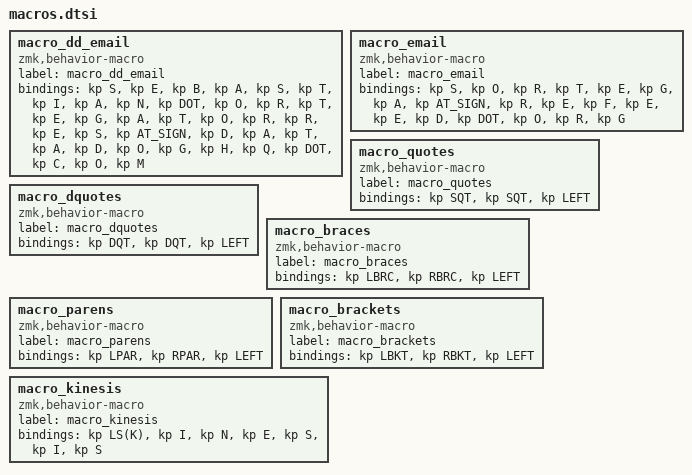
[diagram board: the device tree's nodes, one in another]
macro_dd_email: macro_dd_email{
compatible = "zmk,behavior-macro";
label = "macro_dd_email";
#binding-cells = <0>;
bindings = <&kp S>, <&kp E>, <&kp B>, <&kp A>, <&kp S>, <&kp T>, <&kp I>, <&kp A>, <&kp N>, <&kp DOT>, <&kp O>, <&kp R>, <&kp T>, <&kp E>, <&kp G>, <&kp A>, <&kp T>, <&kp O>, <&kp R>, <&kp R>, <&kp E>, <&kp S>, <&kp AT_SIGN>, <&kp D>, <&kp A>, <&kp T>, <&kp A>, <&kp D>, <&kp O>, <&kp G>, <&kp H>, <&kp Q>, <&kp DOT>, <&kp C>, <&kp O>, <&kp M>;
};
macro_email: macro_email{
compatible = "zmk,behavior-macro";
label = "macro_email";
#binding-cells = <0>;
bindings = <&kp S>, <&kp O>, <&kp R>, <&kp T>, <&kp E>, <&kp G>, <&kp A>, <&kp AT_SIGN>, <&kp R>, <&kp E>, <&kp F>, <&kp E>, <&kp E>, <&kp D>, <&kp DOT>, <&kp O>, <&kp R>, <&kp G>;
};
macro_quotes: macro_quotes{
compatible = "zmk,behavior-macro";
label = "macro_quotes";
#binding-cells = <0>;
bindings = <&kp SQT>, <&kp SQT>, <&kp LEFT>;
};
macro_dquotes: macro_dquotes{
compatible = "zmk,behavior-macro";
label = "macro_dquotes";
#binding-cells = <0>;
bindings = <&kp DQT>, <&kp DQT>, <&kp LEFT>;
};
macro_braces: macro_braces{
compatible = "zmk,behavior-macro";
label = "macro_braces";
#binding-cells = <0>;
bindings = <&kp LBRC>, <&kp RBRC>, <&kp LEFT>;
};
macro_parens: macro_parens{
compatible = "zmk,behavior-macro";
label = "macro_parens";
#binding-cells = <0>;
bindings = <&kp LPAR>, <&kp RPAR>, <&kp LEFT>;
};
macro_brackets: macro_brackets{
compatible = "zmk,behavior-macro";
label = "macro_brackets";
#binding-cells = <0>;
bindings = <&kp LBKT>, <&kp RBKT>, <&kp LEFT>;
};
macro_kinesis: macro_kinesis{
compatible = "zmk,behavior-macro";
label = "macro_kinesis";
#binding-cells = <0>;
bindings = <&kp LS(K)>, <&kp I>, <&kp N>, <&kp E>, <&kp S>, <&kp I>, <&kp S>;
};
